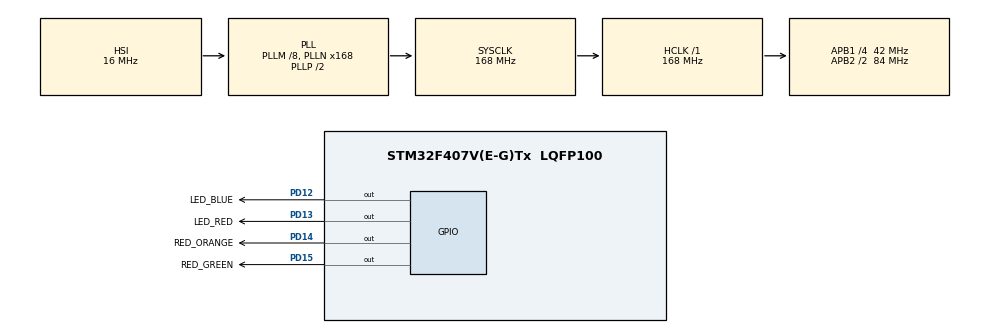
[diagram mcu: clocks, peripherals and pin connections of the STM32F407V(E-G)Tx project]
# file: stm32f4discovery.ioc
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Mcu.Family=STM32F4
Mcu.Name=STM32F407V(E-G)Tx
Mcu.Package=LQFP100
NVIC.PriorityGroup=NVIC_PRIORITYGROUP_0
PD12.GPIO_Label=LED_BLUE
PD12.Signal=GPIO_Output
PD13.GPIO_Label=LED_RED
PD13.Signal=GPIO_Output
PD14.GPIO_Label=RED_ORANGE
PD14.Signal=GPIO_Output
PD15.GPIO_Label=RED_GREEN
PD15.Signal=GPIO_Output
ProjectManager.HeapSize=0x200
ProjectManager.StackSize=0x400
ProjectManager.TargetToolchain=Makefile
RCC.48MHZClocksFreq_Value=48000000
RCC.AHBFreq_Value=168000000
RCC.APB1CLKDivider=RCC_HCLK_DIV4
RCC.APB1Freq_Value=42000000
RCC.APB1TimFreq_Value=84000000
RCC.APB2CLKDivider=RCC_HCLK_DIV2
RCC.APB2Freq_Value=84000000
RCC.APB2TimFreq_Value=168000000
RCC.CortexFreq_Value=168000000
RCC.HCLKFreq_Value=168000000
RCC.HSE_VALUE=8000000
RCC.HSI_VALUE=16000000
RCC.LSE_VALUE=32768
RCC.PLLM=8
RCC.PLLN=168
RCC.PLLQ=7
RCC.SYSCLKFreq_VALUE=168000000
RCC.SYSCLKSource=RCC_SYSCLKSOURCE_PLLCLK
RCC.VCOOutputFreq_Value=336000000
board=STM32F4DISCOVERY

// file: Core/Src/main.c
/* USER CODE BEGIN Header */
/**
 ******************************************************************************
 * @file           : main.c
 * @brief          : Main program body
 ******************************************************************************
 ** This notice applies to any and all portions of this file
 * that are not between comment pairs USER CODE BEGIN and
 * USER CODE END. Other portions of this file, whether
 * inserted by the user or by software development tools
 * are owned by their respective copyright owners.
 *
 * COPYRIGHT(c) 2019 STMicroelectronics
 *
 * Redistribution and use in source and binary forms, with or without
 *modification, are permitted provided that the following conditions are met:
 *   1. Redistributions of source code must retain the above copyright notice,
 *      this list of conditions and the following disclaimer.
 *   2. Redistributions in binary form must reproduce the above copyright
 *notice, this list of conditions and the following disclaimer in the
 *documentation and/or other materials provided with the distribution.
 *   3. Neither the name of STMicroelectronics nor the names of its contributors
 *      may be used to endorse or promote products derived from this software
 *      without specific prior written permission.
 *
 * THIS SOFTWARE IS PROVIDED BY THE COPYRIGHT HOLDERS AND CONTRIBUTORS "AS IS"
 * AND ANY EXPRESS OR IMPLIED WARRANTIES, INCLUDING, BUT NOT LIMITED TO, THE
 * IMPLIED WARRANTIES OF MERCHANTABILITY AND FITNESS FOR A PARTICULAR PURPOSE
 *ARE DISCLAIMED. IN NO EVENT SHALL THE COPYRIGHT HOLDER OR CONTRIBUTORS BE
 *LIABLE FOR ANY DIRECT, INDIRECT, INCIDENTAL, SPECIAL, EXEMPLARY, OR
 *CONSEQUENTIAL DAMAGES (INCLUDING, BUT NOT LIMITED TO, PROCUREMENT OF
 *SUBSTITUTE GOODS OR SERVICES; LOSS OF USE, DATA, OR PROFITS; OR BUSINESS
 *INTERRUPTION) HOWEVER CAUSED AND ON ANY THEORY OF LIABILITY, WHETHER IN
 *CONTRACT, STRICT LIABILITY, OR TORT (INCLUDING NEGLIGENCE OR OTHERWISE)
 *ARISING IN ANY WAY OUT OF THE USE OF THIS SOFTWARE, EVEN IF ADVISED OF THE
 *POSSIBILITY OF SUCH DAMAGE.
 *
 ******************************************************************************
 */
/* USER CODE END Header */

#include "main.h"
#include "gpio.h"

void SystemClock_Config(void);
/* USER CODE BEGIN PFP */
int app_main(void);
/* USER CODE END PFP */

int main(void)
{

  /* MCU Configuration--------------------------------------------------------*/

  /* Reset of all peripherals, Initializes the Flash interface and the Systick. */
  HAL_Init();

  /* Configure the system clock */
  SystemClock_Config();

  /* USER CODE BEGIN SysInit */
  initialise_monitor_handles();
  /* USER CODE END SysInit */

  /* Initialize all configured peripherals */
  MX_GPIO_Init();

  /* Infinite loop */

    /* USER CODE BEGIN 3 */
  _exit(app_main());
  /* USER CODE END 3 */
}

void SystemClock_Config(void)
{
  RCC_OscInitTypeDef RCC_OscInitStruct = {0};
  RCC_ClkInitTypeDef RCC_ClkInitStruct = {0};

  /** Configure the main internal regulator output voltage
  */
  __HAL_RCC_PWR_CLK_ENABLE();
  __HAL_PWR_VOLTAGESCALING_CONFIG(PWR_REGULATOR_VOLTAGE_SCALE1);
  /** Initializes the CPU, AHB and APB busses clocks
  */
  RCC_OscInitStruct.OscillatorType = RCC_OSCILLATORTYPE_HSI;
  RCC_OscInitStruct.HSIState = RCC_HSI_ON;
  RCC_OscInitStruct.HSICalibrationValue = RCC_HSICALIBRATION_DEFAULT;
  RCC_OscInitStruct.PLL.PLLState = RCC_PLL_ON;
  RCC_OscInitStruct.PLL.PLLSource = RCC_PLLSOURCE_HSI;
  RCC_OscInitStruct.PLL.PLLM = 8;
  RCC_OscInitStruct.PLL.PLLN = 168;
  RCC_OscInitStruct.PLL.PLLP = RCC_PLLP_DIV2;
  RCC_OscInitStruct.PLL.PLLQ = 7;
  if (HAL_RCC_OscConfig(&RCC_OscInitStruct) != HAL_OK)
  {
    Error_Handler();
  }
  /** Initializes the CPU, AHB and APB busses clocks
  */
  RCC_ClkInitStruct.ClockType = RCC_CLOCKTYPE_HCLK|RCC_CLOCKTYPE_SYSCLK
                              |RCC_CLOCKTYPE_PCLK1|RCC_CLOCKTYPE_PCLK2;
  RCC_ClkInitStruct.SYSCLKSource = RCC_SYSCLKSOURCE_PLLCLK;
  RCC_ClkInitStruct.AHBCLKDivider = RCC_SYSCLK_DIV1;
  RCC_ClkInitStruct.APB1CLKDivider = RCC_HCLK_DIV4;
  RCC_ClkInitStruct.APB2CLKDivider = RCC_HCLK_DIV2;

  if (HAL_RCC_ClockConfig(&RCC_ClkInitStruct, FLASH_LATENCY_5) != HAL_OK)
  {
    Error_Handler();
  }
}

void Error_Handler(void)
{
}

#ifdef  USE_FULL_ASSERT
/**
  * @brief  Reports the name of the source file and the source line number
  *         where the assert_param error has occurred.
  * @param  file: pointer to the source file name
  * @param  line: assert_param error line source number
  * @retval None
  */
void assert_failed(uint8_t *file, uint32_t line)
{
  /* USER CODE BEGIN 6 */
  /* User can add his own implementation to report the file name and line
     number,
     tex: printf("Wrong parameters value: file %s on line %d\r\n", file, line)
   */
  /* USER CODE END 6 */
}
#endif /* USE_FULL_ASSERT */

/************************ (C) COPYRIGHT STMicroelectronics *****END OF FILE****/
